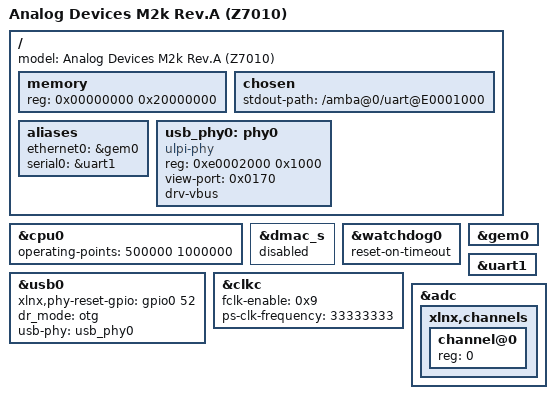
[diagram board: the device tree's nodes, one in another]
/*
 * ZYNQ M2k (Z7010)
 *
 * Copyright (C) 2017 Analog Devices Inc.
 *
 * Licensed under the GPL-2.
 */
#include "zynq-7000.dtsi"

#include <dt-bindings/interrupt-controller/irq.h>

/ {
	model = "Analog Devices M2k Rev.A (Z7010)";

	memory {
		device_type = "memory";
		reg = <0x00000000 0x20000000>;
	};

	chosen {
		stdout-path = "/amba@0/uart@E0001000";
	};

	aliases: aliases {
		ethernet0 = &gem0;
		serial0 = &uart1;
	};

	usb_phy0: phy0 {
		compatible = "ulpi-phy";
		#phy-cells = <0>;
		reg = <0xe0002000 0x1000>;
		view-port = <0x0170>;
		drv-vbus;
	};

};

&cpu0 {
	operating-points = <
		/* kHz    uV */
		500000  1000000
	>;
};

&dmac_s {
	status = "disabled";
};

&watchdog0 {
	status = "okay";
	reset-on-timeout;
};

&gem0 {
	status = "okay";
};

&uart1 {
	status = "okay";
};

&usb0 {
	xlnx,phy-reset-gpio = <&gpio0 52 0>;
	dr_mode = "otg";
	status = "okay";
	usb-phy = <&usb_phy0>;
};

&clkc {
	fclk-enable = <0x9>;
	ps-clk-frequency = <33333333>;
};

&adc {
	xlnx,channels {
		#address-cells = <1>;
		#size-cells = <0>;
		channel@0 {
			reg = <0>;
		};
	};
};
